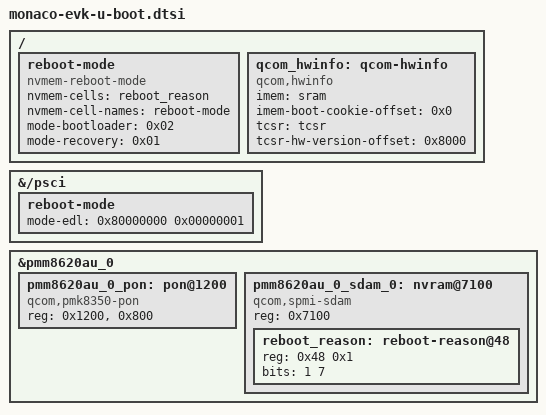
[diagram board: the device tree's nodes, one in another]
// SPDX-License-Identifier: BSD-3-Clause
/*
 * Copyright (c) Qualcomm Technologies, Inc. and/or its subsidiaries.
 */

/* Enter Qualcomm EDL/download mode via "reset -edl". */
&{/psci} {
	reboot-mode {
		mode-edl = <0x80000000 0x00000001>;
	};
};

/ {
	reboot-mode {
		compatible = "nvmem-reboot-mode";
		nvmem-cells = <&reboot_reason>;
		nvmem-cell-names = "reboot-mode";

		mode-bootloader = <0x02>;
		mode-recovery   = <0x01>;
	};
};

&pmm8620au_0 {
	pmm8620au_0_pon: pon@1200 {
		compatible = "qcom,pmk8350-pon";
		reg = <0x1200>, <0x800>;
		reg-names = "hlos", "pbs";
	};

	pmm8620au_0_sdam_0: nvram@7100 {
		compatible = "qcom,spmi-sdam";
		reg = <0x7100>;
		#address-cells = <1>;
		#size-cells = <1>;
		ranges = <0x0 0x7100 0x100>;

		reboot_reason: reboot-reason@48 {
			reg = <0x48 0x1>;
			bits = <1 7>;
		};
	};
};

/ {
	qcom_hwinfo: qcom-hwinfo {
		compatible = "qcom,hwinfo";

		imem = <&sram>;
		imem-boot-cookie-offset = <0x0>;

		tcsr = <&tcsr>;
		tcsr-hw-version-offset = <0x8000>;
	};
};
